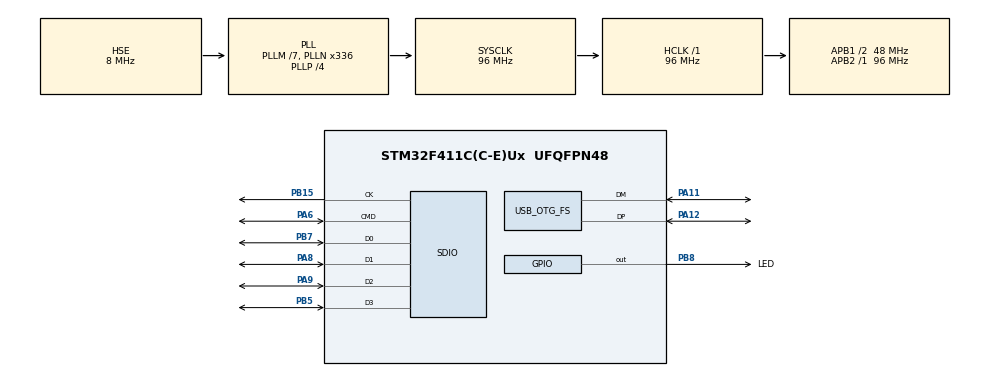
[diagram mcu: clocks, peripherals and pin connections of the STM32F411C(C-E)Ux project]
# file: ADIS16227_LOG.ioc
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Mcu.Family=STM32F4
Mcu.Name=STM32F411C(C-E)Ux
Mcu.Package=UFQFPN48
NVIC.OTG_FS_IRQn=true\:0\:0\:false\:false\:true\:false
NVIC.PriorityGroup=NVIC_PRIORITYGROUP_4
PA11.Mode=Device_Only
PA11.Signal=USB_OTG_FS_DM
PA12.Mode=Device_Only
PA12.Signal=USB_OTG_FS_DP
PA13.Mode=Serial_Wire
PA13.Signal=SYS_JTMS-SWDIO
PA14.Mode=Serial_Wire
PA14.Signal=SYS_JTCK-SWCLK
PA6.Mode=SD_4_bits_Wide_bus
PA6.Signal=SDIO_CMD
PA8.Mode=SD_4_bits_Wide_bus
PA8.Signal=SDIO_D1
PA9.Mode=SD_4_bits_Wide_bus
PA9.Signal=SDIO_D2
PB15.Mode=SD_4_bits_Wide_bus
PB15.Signal=SDIO_CK
PB5.Mode=SD_4_bits_Wide_bus
PB5.Signal=SDIO_D3
PB7.Mode=SD_4_bits_Wide_bus
PB7.Signal=SDIO_D0
PB8.GPIO_Label=LED
PB8.Signal=GPIO_Output
PH0\ -\ OSC_IN.Mode=HSE-External-Oscillator
PH0\ -\ OSC_IN.Signal=RCC_OSC_IN
PH1\ -\ OSC_OUT.Mode=HSE-External-Oscillator
PH1\ -\ OSC_OUT.Signal=RCC_OSC_OUT
ProjectManager.HeapSize=0x2000
ProjectManager.StackSize=0x4000
ProjectManager.TargetToolchain=EWARM V8
RCC.48MHZClocksFreq_Value=48000000.00000001
RCC.AHBFreq_Value=96000000.00000001
RCC.APB1CLKDivider=RCC_HCLK_DIV2
RCC.APB1Freq_Value=48000000.00000001
RCC.APB1TimFreq_Value=96000000.00000001
RCC.APB2Freq_Value=96000000.00000001
RCC.APB2TimFreq_Value=96000000.00000001
RCC.CortexFreq_Value=96000000.00000001
RCC.HCLKFreq_Value=96000000.00000001
RCC.HSE_VALUE=8000000
RCC.HSI_VALUE=16000000
RCC.LSE_VALUE=32768
RCC.PLLM=7
RCC.PLLN=336
RCC.PLLP=RCC_PLLP_DIV4
RCC.PLLQ=8
RCC.SYSCLKFreq_VALUE=96000000.00000001
RCC.SYSCLKSource=RCC_SYSCLKSOURCE_PLLCLK
RCC.VCOOutputFreq_Value=384000000.00000006
USB_DEVICE.CLASS_NAME_FS=CDC
USB_DEVICE.VirtualMode=Cdc
USB_DEVICE.VirtualModeFS=Cdc_FS
USB_OTG_FS.VirtualMode=Device_Only
VP_USB_DEVICE_VS_USB_DEVICE_CDC_FS.Mode=CDC_FS
board=custom

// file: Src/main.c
/**
  ******************************************************************************
  * @file           : main.c
  * @brief          : Main program body
  ******************************************************************************
  * This notice applies to any and all portions of this file
  * that are not between comment pairs USER CODE BEGIN and
  * USER CODE END. Other portions of this file, whether
  * inserted by the user or by software development tools
  * are owned by their respective copyright owners.
  *
  * Copyright (c) 2018 STMicroelectronics International N.V.
  * All rights reserved.
  *
  * Redistribution and use in source and binary forms, with or without
  * modification, are permitted, provided that the following conditions are met:
  *
  * 1. Redistribution of source code must retain the above copyright notice,
  *    this list of conditions and the following disclaimer.
  * 2. Redistributions in binary form must reproduce the above copyright notice,
  *    this list of conditions and the following disclaimer in the documentation
  *    and/or other materials provided with the distribution.
  * 3. Neither the name of STMicroelectronics nor the names of other
  *    contributors to this software may be used to endorse or promote products
  *    derived from this software without specific written permission.
  * 4. This software, including modifications and/or derivative works of this
  *    software, must execute solely and exclusively on microcontroller or
  *    microprocessor devices manufactured by or for STMicroelectronics.
  * 5. Redistribution and use of this software other than as permitted under
  *    this license is void and will automatically terminate your rights under
  *    this license.
  *
  * THIS SOFTWARE IS PROVIDED BY STMICROELECTRONICS AND CONTRIBUTORS "AS IS"
  * AND ANY EXPRESS, IMPLIED OR STATUTORY WARRANTIES, INCLUDING, BUT NOT
  * LIMITED TO, THE IMPLIED WARRANTIES OF MERCHANTABILITY, FITNESS FOR A
  * PARTICULAR PURPOSE AND NON-INFRINGEMENT OF THIRD PARTY INTELLECTUAL PROPERTY
  * RIGHTS ARE DISCLAIMED TO THE FULLEST EXTENT PERMITTED BY LAW. IN NO EVENT
  * SHALL STMICROELECTRONICS OR CONTRIBUTORS BE LIABLE FOR ANY DIRECT, INDIRECT,
  * INCIDENTAL, SPECIAL, EXEMPLARY, OR CONSEQUENTIAL DAMAGES (INCLUDING, BUT NOT
  * LIMITED TO, PROCUREMENT OF SUBSTITUTE GOODS OR SERVICES; LOSS OF USE, DATA,
  * OR PROFITS; OR BUSINESS INTERRUPTION) HOWEVER CAUSED AND ON ANY THEORY OF
  * LIABILITY, WHETHER IN CONTRACT, STRICT LIABILITY, OR TORT (INCLUDING
  * NEGLIGENCE OR OTHERWISE) ARISING IN ANY WAY OUT OF THE USE OF THIS SOFTWARE,
  * EVEN IF ADVISED OF THE POSSIBILITY OF SUCH DAMAGE.
  *
  ******************************************************************************
  */
#include "main.h"
#include "stm32f4xx_hal.h"
#include "usb_device.h"

/* USER CODE BEGIN Includes */
#include "usbd_cdc.h"
/* USER CODE END Includes */

SD_HandleTypeDef hsd;

/* USER CODE BEGIN PV */
/* Private variables ---------------------------------------------------------*/

/* USER CODE END PV */

void SystemClock_Config(void);
static void MX_GPIO_Init(void);
static void MX_SDIO_SD_Init(void);

/* USER CODE BEGIN PFP */
/* Private function prototypes -----------------------------------------------*/

/* USER CODE END PFP */

/* USER CODE BEGIN 0 */
unsigned char cdc_rx_buffer[64];
int cdc_rx_flag = 0;
/* USER CODE END 0 */

int main(void)
{

  /* MCU Configuration----------------------------------------------------------*/

  /* Reset of all peripherals, Initializes the Flash interface and the Systick. */
  HAL_Init();

  /* Configure the system clock */
  SystemClock_Config();

  /* Initialize all configured peripherals */
  MX_GPIO_Init();
  MX_SDIO_SD_Init();
  MX_USB_DEVICE_Init();

  /* Infinite loop */
  /* USER CODE BEGIN WHILE */
  while (1)
  {
    if(cdc_rx_flag > 0)
    {
      USBD_LL_Transmit(&hUsbDeviceFS,
                       CDC_IN_EP,
                       cdc_rx_buffer,
                       cdc_rx_flag);
      cdc_rx_flag = 0;
    }
  /* USER CODE END WHILE */

  }

}

void SystemClock_Config(void)
{

  RCC_OscInitTypeDef RCC_OscInitStruct;
  RCC_ClkInitTypeDef RCC_ClkInitStruct;

    /**Configure the main internal regulator output voltage
    */
  __HAL_RCC_PWR_CLK_ENABLE();

  __HAL_PWR_VOLTAGESCALING_CONFIG(PWR_REGULATOR_VOLTAGE_SCALE1);

    /**Initializes the CPU, AHB and APB busses clocks
    */
  RCC_OscInitStruct.OscillatorType = RCC_OSCILLATORTYPE_HSE;
  RCC_OscInitStruct.HSEState = RCC_HSE_ON;
  RCC_OscInitStruct.PLL.PLLState = RCC_PLL_ON;
  RCC_OscInitStruct.PLL.PLLSource = RCC_PLLSOURCE_HSE;
  RCC_OscInitStruct.PLL.PLLM = 7;
  RCC_OscInitStruct.PLL.PLLN = 336;
  RCC_OscInitStruct.PLL.PLLP = RCC_PLLP_DIV4;
  RCC_OscInitStruct.PLL.PLLQ = 8;
  if (HAL_RCC_OscConfig(&RCC_OscInitStruct) != HAL_OK)
  {
    _Error_Handler(__FILE__, __LINE__);
  }

    /**Initializes the CPU, AHB and APB busses clocks
    */
  RCC_ClkInitStruct.ClockType = RCC_CLOCKTYPE_HCLK|RCC_CLOCKTYPE_SYSCLK
                              |RCC_CLOCKTYPE_PCLK1|RCC_CLOCKTYPE_PCLK2;
  RCC_ClkInitStruct.SYSCLKSource = RCC_SYSCLKSOURCE_PLLCLK;
  RCC_ClkInitStruct.AHBCLKDivider = RCC_SYSCLK_DIV1;
  RCC_ClkInitStruct.APB1CLKDivider = RCC_HCLK_DIV2;
  RCC_ClkInitStruct.APB2CLKDivider = RCC_HCLK_DIV1;

  if (HAL_RCC_ClockConfig(&RCC_ClkInitStruct, FLASH_LATENCY_3) != HAL_OK)
  {
    _Error_Handler(__FILE__, __LINE__);
  }

    /**Configure the Systick interrupt time
    */
  HAL_SYSTICK_Config(HAL_RCC_GetHCLKFreq()/1000);

    /**Configure the Systick
    */
  HAL_SYSTICK_CLKSourceConfig(SYSTICK_CLKSOURCE_HCLK);

  /* SysTick_IRQn interrupt configuration */
  HAL_NVIC_SetPriority(SysTick_IRQn, 0, 0);
}

/* SDIO init function */
static void MX_SDIO_SD_Init(void)
{

  hsd.Instance = SDIO;
  hsd.Init.ClockEdge = SDIO_CLOCK_EDGE_RISING;
  hsd.Init.ClockBypass = SDIO_CLOCK_BYPASS_DISABLE;
  hsd.Init.ClockPowerSave = SDIO_CLOCK_POWER_SAVE_DISABLE;
  hsd.Init.BusWide = SDIO_BUS_WIDE_1B;
  hsd.Init.HardwareFlowControl = SDIO_HARDWARE_FLOW_CONTROL_DISABLE;
  hsd.Init.ClockDiv = 0;
  if (HAL_SD_Init(&hsd) != HAL_OK)
  {
    _Error_Handler(__FILE__, __LINE__);
  }

  if (HAL_SD_ConfigWideBusOperation(&hsd, SDIO_BUS_WIDE_4B) != HAL_OK)
  {
    _Error_Handler(__FILE__, __LINE__);
  }

}

/** Configure pins as
        * Analog
        * Input
        * Output
        * EVENT_OUT
        * EXTI
*/
static void MX_GPIO_Init(void)
{

  GPIO_InitTypeDef GPIO_InitStruct;

  /* GPIO Ports Clock Enable */
  __HAL_RCC_GPIOH_CLK_ENABLE();
  __HAL_RCC_GPIOA_CLK_ENABLE();
  __HAL_RCC_GPIOB_CLK_ENABLE();

  /*Configure GPIO pin Output Level */
  HAL_GPIO_WritePin(LED_GPIO_Port, LED_Pin, GPIO_PIN_RESET);

  /*Configure GPIO pin : LED_Pin */
  GPIO_InitStruct.Pin = LED_Pin;
  GPIO_InitStruct.Mode = GPIO_MODE_OUTPUT_PP;
  GPIO_InitStruct.Pull = GPIO_NOPULL;
  GPIO_InitStruct.Speed = GPIO_SPEED_FREQ_LOW;
  HAL_GPIO_Init(LED_GPIO_Port, &GPIO_InitStruct);

}

void _Error_Handler(char *file, int line)
{
  while(1)
  {
  }
}

/************************ (C) COPYRIGHT STMicroelectronics *****END OF FILE****/
